VERSION ""

NS_ :

BS_:

BU_: Device Host
VAL_TABLE_ vtBrkPedlSw 3 "Not available" 2 "Error" 1 "Brake Pedal Depressed" 0 "Brake Pedal Released" ;
VAL_TABLE_ vtOnOff 3 "Not available" 2 "Error" 1 "On" 0 "Off" ;
VAL_TABLE_ vAction_t 3 "va_Take_no_action" 2 "va_Reserved" 1 "va_On" 0 "va_Off" ;
VAL_TABLE_ vtDtsVehDirMov 3 "NA" 2 "REVERSE" 1 "FORWARD" 0 "STANDSTILL" ;

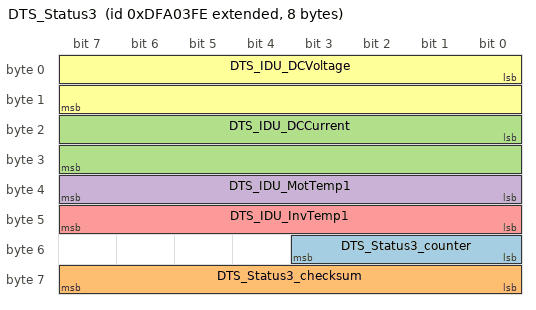
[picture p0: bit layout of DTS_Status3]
BO_ 2381972478 DTS_Status3: 8 Vector__XXX
 SG_ DTS_Status3_counter : 48|4@1+ (1,0) [0|15] "" Vector__XXX
 SG_ DTS_Status3_checksum : 56|8@1+ (1,0) [0|255] "" Vector__XXX
 SG_ DTS_IDU_DCCurrent : 16|16@1+ (0.1,-3276.8) [-3276.8|3276.7] "A" Vector__XXX
 SG_ DTS_IDU_MotTemp1 : 32|8@1+ (1,-40) [-40|215] "degC" Vector__XXX
 SG_ DTS_IDU_InvTemp1 : 40|8@1+ (1,-40) [-40|215] "degC" Vector__XXX
 SG_ DTS_IDU_DCVoltage : 0|16@1+ (0.02,0) [0|1310.7] "V" Vector__XXX

CM_ "Arrival Drivetrain Controller Database.
$DBC storage: //depot/auto/dbc/Software_Modules/Drivetrain_Controller/ArrivalDTC/ $
$Change: 0 $
$DateTime: 2020/11/02 14:30:00 $
$Revision: #1 $
$Author: lyamin@arrival.com $
";
CM_ BO_ 2381972478 "Message with general information about current Drivetrain System state";
CM_ SG_ 2381972478 DTS_IDU_DCCurrent "Drivetrain System IDU DC Voltage";
CM_ SG_ 2381972478 DTS_IDU_MotTemp1 "Drivetrain System Motor Temperature1";
CM_ SG_ 2381972478 DTS_IDU_InvTemp1 "Drivetrain System Inverter Temperature1";
CM_ SG_ 2381972478 DTS_IDU_DCVoltage "Drivetrain System IDU DC Voltage";
BA_DEF_  "BusType" STRING ;
BA_DEF_  "DBName" STRING ;
BA_DEF_  "DatabaseVersion" STRING ;
BA_DEF_ BO_  "GenMsgCycleTime" INT 0 3600000;
BA_DEF_ BO_  "GenMsgILSupport" ENUM  "No","Yes";
BA_DEF_ BO_  "GenMsgRequestable" INT 0 1;
BA_DEF_ BO_  "GenMsgSendType" ENUM  "cyclic","NotUsed","NotUsed","NotUsed","NotUsed","NotUsed","NotUsed","IfActive","noMsgSendType";
BA_DEF_ BO_  "Producer" STRING ;
BA_DEF_ SG_  "GenSigEVName" STRING ;
BA_DEF_ SG_  "GenSigILSupport" ENUM  "No","Yes";
BA_DEF_ SG_  "GenSigSendType" ENUM  "Cyclic","OnWrite","OnWriteWithRepetition","OnChange","OnChangeWithRepetition","IfActive","IfActiveWithRepetition","NoSigSendType";
BA_DEF_ SG_  "GenSigStartValue" INT 0 2147483647;
BA_DEF_ BU_  "NmStationAddress" INT 0 255;
BA_DEF_  "ProtocolType" STRING ;
BA_DEF_  "SAE_J1939_21_SpecVersion" STRING ;
BA_DEF_  "SAE_J1939_71_SpecVersion" STRING ;
BA_DEF_  "SAE_J1939_73_SpecVersion" STRING ;
BA_DEF_  "SAE_J1939_75_SpecVersion" STRING ;
BA_DEF_  "SAE_J1939_81_SpecVersion" STRING ;
BA_DEF_  "SAE_J1939_DA_SpecVersion" STRING ;
BA_DEF_ SG_  "SigType" ENUM  "Default","Range","RangeSigned","ASCII","Discrete","Control","ReferencePGN","DTC","StringDelimiter","StringLength","StringLengthControl","MessageCounter","MessageChecksum";
BA_DEF_ BO_  "VFrameFormat" ENUM  "StandardCAN","ExtendedCAN","reserved","J1939PG","reserved","reserved","reserved","reserved","reserved","reserved","reserved","reserved","reserved","reserved","StandardCAN_FD","ExtendedCAN_FD";
BA_DEF_DEF_  "BusType" "";
BA_DEF_DEF_ "Producer" "DTS" ;
BA_DEF_DEF_  "DBName" "";
BA_DEF_DEF_  "DatabaseVersion" "";
BA_DEF_DEF_  "GenMsgCycleTime" 0;
BA_DEF_DEF_  "GenMsgILSupport" "Yes";
BA_DEF_DEF_  "GenMsgRequestable" 1;
BA_DEF_DEF_  "GenMsgSendType" "noMsgSendType";
BA_DEF_DEF_  "GenSigEVName" "Env@Nodename_@Signame";
BA_DEF_DEF_  "GenSigILSupport" "Yes";
BA_DEF_DEF_  "GenSigSendType" "NoSigSendType";
BA_DEF_DEF_  "GenSigStartValue" 0;
BA_DEF_DEF_  "NmStationAddress" 254;
BA_DEF_DEF_  "ProtocolType" "";
BA_DEF_DEF_  "SAE_J1939_21_SpecVersion" "";
BA_DEF_DEF_  "SAE_J1939_71_SpecVersion" "";
BA_DEF_DEF_  "SAE_J1939_73_SpecVersion" "";
BA_DEF_DEF_  "SAE_J1939_75_SpecVersion" "";
BA_DEF_DEF_  "SAE_J1939_81_SpecVersion" "";
BA_DEF_DEF_  "SAE_J1939_DA_SpecVersion" "";
BA_DEF_DEF_  "SigType" "Default";
BA_DEF_DEF_  "VFrameFormat" "J1939PG";
BA_ "BusType" "CAN";
BA_ "DatabaseVersion" "1.0";
BA_ "ProtocolType" "J1939";
BA_ "SAE_J1939_21_SpecVersion" "2006-10";
BA_ "SAE_J1939_71_SpecVersion" "2012-10";
BA_ "SAE_J1939_73_SpecVersion" "2012-10";
BA_ "SAE_J1939_75_SpecVersion" "2012-05";
BA_ "SAE_J1939_81_SpecVersion" "2012-05";
BA_ "SAE_J1939_DA_SpecVersion" "2015-01";
BA_ "DBName" "DTS_Status1";
BA_ "GenMsgSendType" BO_ 2381972478 0;
BA_ "GenMsgCycleTime" BO_ 2381972478 100;
BA_ "SigType" SG_ 2381972478 DTS_Status3_counter 11;
BA_ "GenSigSendType" SG_ 2381972478 DTS_Status3_counter 0;
BA_ "SigType" SG_ 2381972478 DTS_Status3_checksum 12;
BA_ "GenSigSendType" SG_ 2381972478 DTS_Status3_checksum 0;
BA_ "SigType" SG_ 2381972478 DTS_IDU_DCCurrent 1;
BA_ "GenSigStartValue" SG_ 2381972478 DTS_IDU_DCCurrent 32768;
BA_ "GenSigStartValue" SG_ 2381972478 DTS_IDU_MotTemp1 40;
BA_ "SigType" SG_ 2381972478 DTS_IDU_MotTemp1 1;
BA_ "GenSigStartValue" SG_ 2381972478 DTS_IDU_InvTemp1 40;
BA_ "SigType" SG_ 2381972478 DTS_IDU_InvTemp1 1;
BA_ "SigType" SG_ 2381972478 DTS_IDU_DCVoltage 1;
